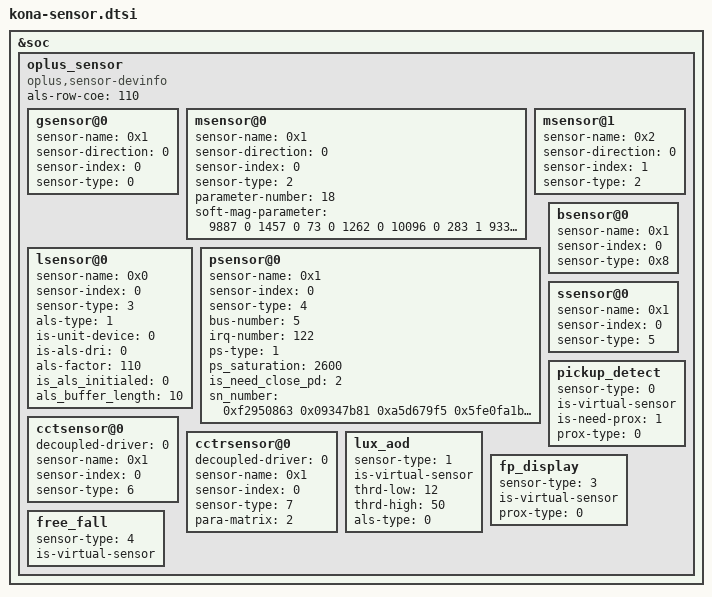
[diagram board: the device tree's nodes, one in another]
&soc {
oplus_sensor {
	compatible = "oplus,sensor-devinfo";
	als-row-coe = <110>;
	/*enum {LSM6DSM = 0x01, BMI160 = 0x02, LSM6DS3 = 0x04};*/
	gsensor@0 {
		sensor-name = <0x1>;//LSM6DSM
		sensor-direction = <0>;
		sensor-index = <0>;//source num
		sensor-type = <0>;//ACCEL
	};
	/* enum {AKM0991X = 0x01, MMC5603 = 0x02};*/
	msensor@0 {
		sensor-name = <0x1>;//AKM09918
		sensor-direction = <0>;
		sensor-index = <0>;
		sensor-type = <2>;//MAG
		parameter-number= <18>;
		//sensor-parameter = <1>;//0-useless;other- to differ special parameter
		soft-mag-parameter = <9887 0 1457 0 73 0 1262 0 10096 0 283 1 933 0 663 1 10867 0>;//e00 sign e01 sign...
	};
	msensor@1 {
		sensor-name = <0x2>;//MMC5603
		sensor-direction = <0>;
		sensor-index = <1>;
		sensor-type = <2>;//MAG
	};
	/*enum {STK3A5X=0x01,TCS3701=0x02,TCS3408=0x04};*/
	lsensor@0 {
		sensor-name = <0x0>;//TCS3408 0-use other driver//compatible old
		sensor-index = <0>;
		sensor-type = <3>;//LIGHT
		als-type = <1>;
		is-unit-device = <0>;
		is-als-dri = <0>;
		als-factor = <110>;
		is_als_initialed = <0>;
		als_buffer_length = <10>;
	};
	psensor@0 {
		sensor-name = <0x1>;//STK33502
		sensor-index = <0>;
		sensor-type = <4>;//PROXIMITY
		bus-number = <5>;
		irq-number = <122>;
		ps-type = <1>;
		ps_saturation = <2600>;
		/*1-need close 2-close has contidition 0-not close*/
		is_need_close_pd = <2>;
		sn_number = <0xf2950863 0x09347b81 0xa5d679f5 0x5fe0fa1b 0xfcfb33ca
			    0x85df9dee 0x30682ac0 0xddf4bc3d 0xb8d72979 0xe83f0a90
			    0x24a9bcf0 0x77d4a0f0 0xb6870ef3 0x15e9693b 0x21858a59
			    0x35a15be7 0x6c682a71 0x45e3d4ee>;
	};
	/*enum {LPS22HH = 0x01, BMP380 = 0x02}*/
	bsensor@0 {
		sensor-name = <0x1>;//LPS22HH
		sensor-index = <0>;
		sensor-type = <0x8>;//BAROMETER
	};
	/* enum {SX9324 = 0x01} */
	ssensor@0 {
		sensor-name = <0x1>;//SX9324
		sensor-index = <0>;
		sensor-type = <5>;//SAR
	};
	/* enum {tcs3408 = 0x01  stk37600 = 0x02} */
	cctsensor@0 {
		decoupled-driver = <0>; //0 - tcs3408 driver; 1 - oplus_cct driver
		sensor-name = <0x1>; //tcs3408
		sensor-index = <0>;
		sensor-type = <6>; //CCT
	};
	cctrsensor@0 {
		decoupled-driver = <0>; //0 - tcs3408 driver; 1 - oplus_cct driver
		sensor-name = <0x1>; //tcs3408
		sensor-index = <0>;
		sensor-type = <7>; //CCT_REAR
		para-matrix = <2>;//0-default
	};
	/*virtual sensor
	enum sensor_algo_id {
		PICKUP_DETECT,
		LUX_AOD,
		TP_GESTURE,
		FP_DISPLAY,
		FREE_FALL,
		CAMERA_PROTECT,
		SENSOR_ALGO_NUM
	}*/
	pickup_detect {
		sensor-type = <0>;//PICKUP_DETECT
		is-virtual-sensor;
		is-need-prox = <1>;
		prox-type = <0>;
	};
	lux_aod {
		sensor-type = <1>; //LUX_AOD
		is-virtual-sensor;
		thrd-low = <12>;
		thrd-high = <50>;
		als-type = <0>;
	};
	fp_display {
		sensor-type = <3>;//FP_DISPLAY
		is-virtual-sensor;
		prox-type = <0>; // 0 - proximity; 1 - proximity_fake
	};
	free_fall {
		sensor-type = <4>;//FREE_FALL
		is-virtual-sensor;
	};
};
};
